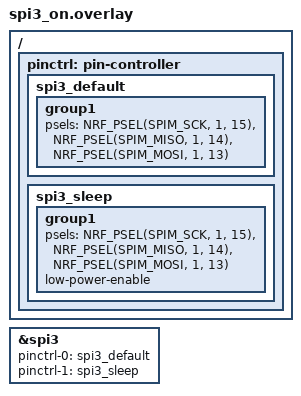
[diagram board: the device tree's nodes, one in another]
/ {
	pinctrl: pin-controller {
		spi3_default: spi3_default {
			group1 {
				psels = <NRF_PSEL(SPIM_SCK, 1, 15)>,
						<NRF_PSEL(SPIM_MISO, 1, 14)>,
						<NRF_PSEL(SPIM_MOSI, 1, 13)>;
			};
		};
		spi3_sleep: spi3_sleep {
			group1 {
				psels = <NRF_PSEL(SPIM_SCK, 1, 15)>,
					<NRF_PSEL(SPIM_MISO, 1, 14)>,
					<NRF_PSEL(SPIM_MOSI, 1, 13)>;
				low-power-enable;
			};
		};
	};
};

&spi3 {
	status = "okay";
	pinctrl-0 = <&spi3_default>;
	pinctrl-1 = <&spi3_sleep>;
	pinctrl-names = "default", "sleep";
};


